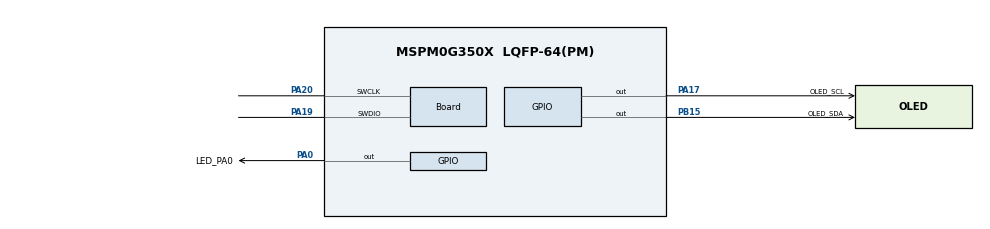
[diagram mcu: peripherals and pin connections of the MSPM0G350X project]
/**
 * @cliArgs --device "MSPM0G350X" --package "LQFP-64(PM)" --part "Default" --product "mspm0_sdk@2.00.01.00"
 * @versions {"tool":"1.20.0+3587"}
 */

/**
 * Import the modules used in this configuration.
 */
const GPIO          = scripting.addModule("/ti/driverlib/GPIO", {}, false);
const GPIO1         = GPIO.addInstance();
const GPIO2         = GPIO.addInstance();
const GPIO3         = GPIO.addInstance();
const SYSCTL        = scripting.addModule("/ti/driverlib/SYSCTL");
const ProjectConfig = scripting.addModule("/ti/project_config/ProjectConfig");

/**
 * Write custom configuration values to the imported modules.
 */
GPIO1.port                          = "PORTA";
GPIO1.$name                         = "USER_GPIO";
GPIO1.associatedPins[0].$name       = "LED_PA0";
GPIO1.associatedPins[0].pin.$assign = "PA0";

const Board                       = scripting.addModule("/ti/driverlib/Board", {}, false);
Board.peripheral.$assign          = "DEBUGSS";
Board.peripheral.swclkPin.$assign = "PA20";
Board.peripheral.swdioPin.$assign = "PA19";

GPIO2.$name                         = "PORTA";
GPIO2.port                          = "PORTA";
GPIO2.associatedPins[0].$name       = "OLED_SCL";
GPIO2.associatedPins[0].pin.$assign = "PA17";

GPIO3.$name                         = "PORTB";
GPIO3.port                          = "PORTB";
GPIO3.associatedPins[0].$name       = "OLED_SDA";
GPIO3.associatedPins[0].pin.$assign = "PB15";

SYSCTL.clockTreeEn = true;

ProjectConfig.deviceSpin = "MSPM0G3507";
